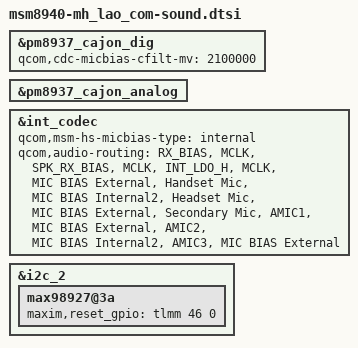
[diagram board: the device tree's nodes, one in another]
/*
 * Copyright (c) 2016, The Linux Foundation. All rights reserved.
 *
 * This program is free software; you can redistribute it and/or modify
 * it under the terms of the GNU General Public License version 2 and
 * only version 2 as published by the Free Software Foundation.
 *
 * This program is distributed in the hope that it will be useful,
 * but WITHOUT ANY WARRANTY; without even the implied warranty of
 * MERCHANTABILITY or FITNESS FOR A PARTICULAR PURPOSE.  See the
 * GNU General Public License for more details.
 */


&pm8937_cajon_dig {
	status = "okay";
	qcom,cdc-micbias-cfilt-mv = <2100000>;
};

&pm8937_cajon_analog {
	status = "okay";
};

&int_codec {
        qcom,msm-hs-micbias-type = "internal";
        qcom,audio-routing =
                "RX_BIAS", "MCLK",
                "SPK_RX_BIAS", "MCLK",
                "INT_LDO_H", "MCLK",
                "MIC BIAS External", "Handset Mic",
                "MIC BIAS Internal2", "Headset Mic",
                "MIC BIAS External", "Secondary Mic",
                "AMIC1", "MIC BIAS External",
                "AMIC2", "MIC BIAS Internal2",
                "AMIC3", "MIC BIAS External";
};

&i2c_2 {
    max98927@3a {
	maxim,reset_gpio = <&tlmm 46 0>;
    };
};
